VERSION ""

NS_ :

BS_:

BU_: Display VN1640A IMU_R LOGGER EPOS RES FSG_LOGGER IO_TEST JETSON ASB AMI ECU RTK IMU_F I2C_RW I2C_SB_L I2C_SB_R I2C_FW HSS_FAN_L HSS_FAN_R HSS_PUMP_L HSS_PUMP_R HSS_RTDS HSS_REAR DIO_AS DIO_DASH AIN_R1 AIN_SB_L AIN_SB_R AIN_F2 AIN_F1
VAL_TABLE_ VT_Car_Status 6 "SCS ERROR" 5 "LC ON" 4 "DRIVE" 3 "Wait for RTD" 2 "RTD OFF" 1 "Wait for TSA" 0 "Undefined | Startup" ;
VAL_TABLE_ VT_CANopen_Request_State 130 "Reset Communication" 129 "Reset Application" 2 "Stopped Mode" 128 "Pre-Operational Mode" 1 "Operational Mode" ;
VAL_TABLE_ VT_CANopen_Node_Status 255 "PRE-OPERATIONAL" 245 "OPERATIONAL" 244 "STOPPED" 240 "BOOTUP" 127 "PRE-OPERATIONAL" 5 "OPERATIONAL" 4 "STOPPED" 0 "BOOTUP" ;
VAL_TABLE_ VT_CANopen_Addressed_Node_ID 17 "RES" 12 "EPOS" 0 "all" ;
VAL_TABLE_ VT_CANopen_Nodes 17 "RES" 12 "EPOS" 0 "all" ;
VAL_TABLE_ VT_LED_States 3 "Error" 2 "Start-up Test" 1 "ON" 0 "OFF" ;
VAL_TABLE_ VT_Corners 3 "Front Left" 2 "Rear Left" 1 "Rear Right" 0 "Front Right" ;
VAL_TABLE_ VT_Sides 1 "Left" 0 "Right" ;

BO_ 3221225472 VECTOR__INDEPENDENT_SIG_MSG: 0 Vector__XXX
 SG_ sig_imu_power_ok : 0|1@1+ (1,0) [0|1] "" Vector__XXX
 SG_ diff_correction_age : 0|8@1+ (1,0) [0|255] "s" Vector__XXX
 SG_ num_space_vehicles : 0|8@1+ (1,0) [0|255] "" Vector__XXX

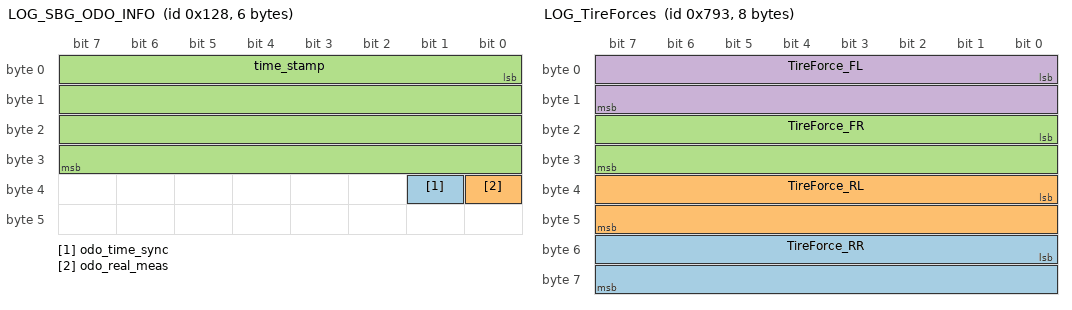
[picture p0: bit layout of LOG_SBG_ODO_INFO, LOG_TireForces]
BO_ 296 LOG_SBG_ODO_INFO: 6 Vector__XXX
 SG_ odo_time_sync : 33|1@1+ (1,0) [0|1] "" Vector__XXX
 SG_ odo_real_meas : 32|1@1+ (1,0) [0|1] "" Vector__XXX
 SG_ time_stamp : 0|32@1+ (1,0) [0|4294967295] "us" Vector__XXX

BO_ 288 HSC_SBG_POSITION_ACC: 6 RTK
 SG_ altitude_acc : 32|16@1+ (0.01,0) [0|655.35] "m" Vector__XXX
 SG_ latitude_acc : 0|16@1+ (0.01,0) [0|655.35] "m" Vector__XXX
 SG_ longitude_acc : 16|16@1+ (0.01,0) [0|655.35] "m" Vector__XXX

BO_ 285 HSC_SBG_EULER_ACC: 6 RTK
 SG_ yaw_acc : 32|16@1+ (0.0001,0) [0|6.5535] "rad" Vector__XXX
 SG_ pitch_acc : 16|16@1+ (0.01,0) [0|655.35] "°" Vector__XXX
 SG_ roll_acc : 0|16@1+ (0.0001,0) [0|6.5535] "rad" Vector__XXX

BO_ 284 HSC_SBG_EULER: 6 RTK
 SG_ yaw : 32|16@1- (0.0001,0) [-3.2768|3.2767] "rad" Vector__XXX
 SG_ pitch : 16|16@1- (0.0001,0) [-3.2768|3.2767] "rad" Vector__XXX
 SG_ roll : 0|16@1- (0.0001,0) [-3.2768|3.2767] "rad" Vector__XXX

BO_ 282 LOG_SBG_EKF_INFO: 4 RTK
 SG_ time_stamp : 0|32@1+ (1,0) [0|4294967295] "us" Vector__XXX

BO_ 277 LOG_SBG_IMU_INFO: 8 RTK
 SG_ temperature : 48|16@1- (0.01,0) [-327.68|327.67] "" Vector__XXX
 SG_ time_stamp : 0|32@1+ (1,0) [0|4294967295] "us" Vector__XXX

BO_ 1939 LOG_TireForces: 8 ECU
 SG_ TireForce_RR : 48|16@1+ (0.02,0) [0|1310.7] "N" Vector__XXX
 SG_ TireForce_RL : 32|16@1+ (0.02,0) [0|1310.7] "N" Vector__XXX
 SG_ TireForce_FR : 16|16@1+ (0.02,0) [0|1310.7] "N" Vector__XXX
 SG_ TireForce_FL : 0|16@1+ (0.02,0) [0|1310.7] "N" Vector__XXX

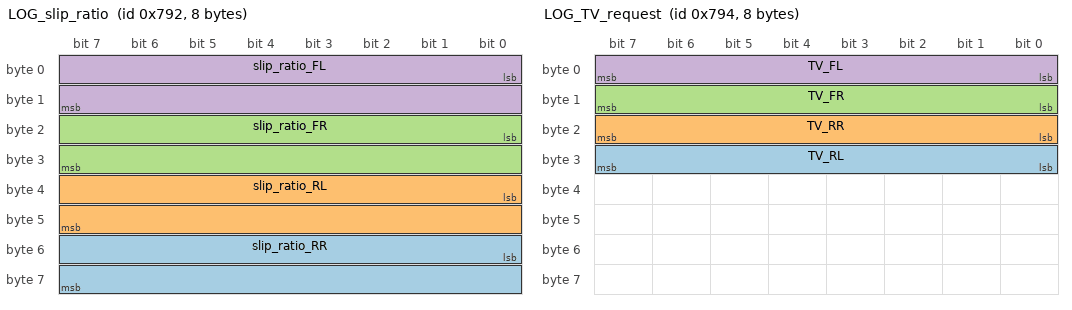
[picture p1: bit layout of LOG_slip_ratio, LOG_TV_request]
BO_ 1938 LOG_slip_ratio: 8 ECU
 SG_ slip_ratio_RR : 48|16@1- (0.01,0) [-327.68|327.67] "rad" Vector__XXX
 SG_ slip_ratio_RL : 32|16@1- (0.01,0) [-327.68|327.67] "rad" Vector__XXX
 SG_ slip_ratio_FR : 16|16@1- (0.01,0) [-327.68|327.67] "rad" Vector__XXX
 SG_ slip_ratio_FL : 0|16@1- (0.01,0) [-327.68|327.67] "rad" Vector__XXX

BO_ 1940 LOG_TV_request: 8 ECU
 SG_ TV_RL : 24|8@1- (0.2,0) [-25.6|25.4] "Nm" Vector__XXX
 SG_ TV_RR : 16|8@1- (0.2,0) [-25.6|25.4] "Nm" Vector__XXX
 SG_ TV_FR : 8|8@1- (0.2,0) [-25.6|25.4] "Nm" Vector__XXX
 SG_ TV_FL : 0|8@1- (0.2,0) [-25.6|25.4] "Nm" Vector__XXX

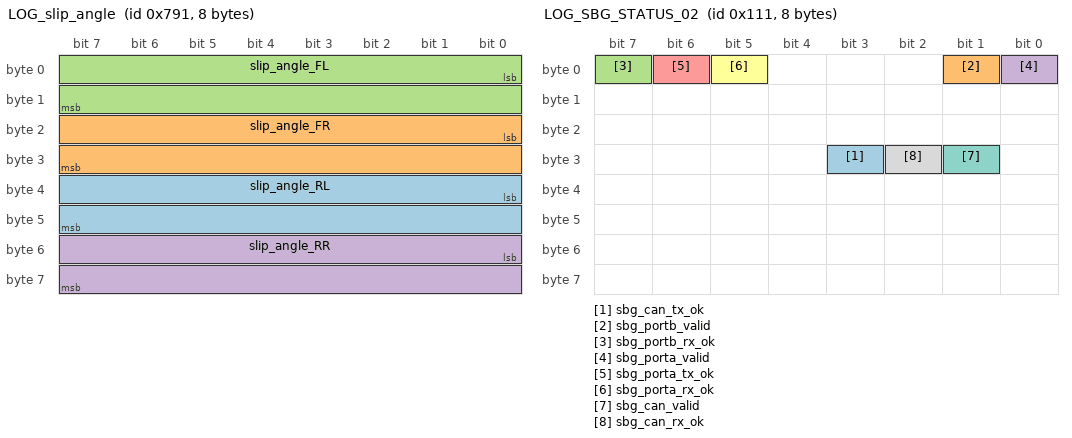
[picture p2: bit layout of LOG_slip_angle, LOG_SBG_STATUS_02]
BO_ 1937 LOG_slip_angle: 8 ECU
 SG_ slip_angle_RL : 32|16@1- (0.01,0) [-327.68|327.67] "rad" Vector__XXX
 SG_ slip_angle_FR : 16|16@1- (0.01,0) [-327.68|327.67] "rad" Vector__XXX
 SG_ slip_angle_FL : 0|16@1- (0.01,0) [-327.68|327.67] "rad" Vector__XXX
 SG_ slip_angle_RR : 48|16@1- (0.01,0) [-327.68|327.67] "rad" Vector__XXX

BO_ 310 HSC_SBG_TRUE_HEADING: 8 RTK
 SG_ pitch : 32|16@1- (0.01,0) [-327.68|327.67] "°" Vector__XXX
 SG_ true_heading_acc : 16|16@1+ (0.01,0) [0|655.35] "°" Vector__XXX
 SG_ true_heading : 0|16@1+ (0.01,0) [0|655.35] "°" Vector__XXX

BO_ 287 HSC_SBG_ALTITUDE: 6 RTK
 SG_ undulation : 32|16@1- (0.005,0) [-163.84|163.835] "m" Vector__XXX
 SG_ altitude : 0|32@1- (0.001,0) [-2147483.648|2147483.647] "m" Vector__XXX

BO_ 286 HSC_SBG_POSITION: 8 RTK
 SG_ longitude : 32|32@1- (1E-007,0) [-214.7483648|214.7483647] "°" Vector__XXX
 SG_ latitude : 0|32@1- (1E-007,0) [-214.7483648|214.7483647] "°" Vector__XXX

BO_ 309 LOG_SBG_HEADING_INFO: 6 RTK
 SG_ time_stamp : 0|32@1+ (1,0) [0|4294967295] "us" Vector__XXX

BO_ 305 LOG_SBG_POS_INFO: 8 RTK
 SG_ time_stamp : 0|32@1+ (1,0) [0|4294967295] "us" Vector__XXX

BO_ 301 LOG_SBG_GPS1_VEL_INFO: 8 RTK
 SG_ time_stamp : 0|32@1+ (1,0) [0|4294967295] "us" Vector__XXX

BO_ 274 LOG_SBG_STATUS_03: 6 RTK

BO_ 273 LOG_SBG_STATUS_02: 8 RTK
 SG_ sbg_can_tx_ok : 27|1@1+ (1,0) [0|1] "" Vector__XXX
 SG_ sbg_portb_valid : 1|1@1+ (1,0) [0|1] "" Vector__XXX
 SG_ sbg_portb_rx_ok : 7|1@1+ (1,0) [0|1] "" Vector__XXX
 SG_ sbg_porta_valid : 0|1@1+ (1,0) [0|1] "" Vector__XXX
 SG_ sbg_porta_tx_ok : 6|1@1+ (1,0) [0|1] "" Vector__XXX
 SG_ sbg_porta_rx_ok : 5|1@1+ (1,0) [0|1] "" Vector__XXX
 SG_ sbg_can_valid : 25|1@1+ (1,0) [0|1] "" Vector__XXX
 SG_ sbg_can_rx_ok : 26|1@1+ (1,0) [0|1] "" Vector__XXX

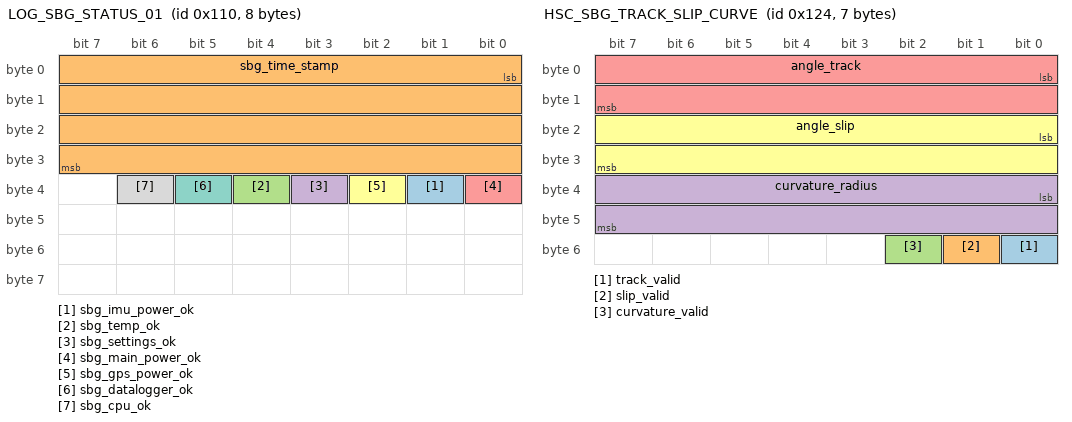
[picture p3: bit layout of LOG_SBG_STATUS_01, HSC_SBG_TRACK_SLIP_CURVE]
BO_ 272 LOG_SBG_STATUS_01: 8 RTK
 SG_ sbg_imu_power_ok : 33|1@1+ (1,0) [0|1] "" Vector__XXX
 SG_ sbg_time_stamp : 0|32@1+ (1,0) [0|4294967295] "us" Vector__XXX
 SG_ sbg_temp_ok : 36|1@1+ (1,0) [0|1] "" Vector__XXX
 SG_ sbg_settings_ok : 35|1@1+ (1,0) [0|1] "" Vector__XXX
 SG_ sbg_main_power_ok : 32|1@1+ (1,0) [0|1] "" Vector__XXX
 SG_ sbg_gps_power_ok : 34|1@1+ (1,0) [0|1] "" Vector__XXX
 SG_ sbg_datalogger_ok : 37|1@1+ (1,0) [0|1] "" Vector__XXX
 SG_ sbg_cpu_ok : 38|1@1+ (1,0) [0|1] "" Vector__XXX

BO_ 292 HSC_SBG_TRACK_SLIP_CURVE: 7 RTK
 SG_ track_valid : 48|1@1+ (1,0) [0|1] "" Vector__XXX
 SG_ slip_valid : 49|1@1+ (1,0) [0|1] "" Vector__XXX
 SG_ curvature_valid : 50|1@1+ (1,0) [0|1] "" Vector__XXX
 SG_ curvature_radius : 32|16@1+ (0.01,0) [0|655.35] "m" Vector__XXX
 SG_ angle_track : 0|16@1- (0.0001,0) [-3.2768|3.2767] "rad" Vector__XXX
 SG_ angle_slip : 16|16@1- (0.0001,0) [-3.2768|3.2767] "rad" Vector__XXX

BO_ 291 HSC_SBG_EKF_VEL_BODY: 6 RTK
 SG_ velocity_z : 32|16@1- (0.01,0) [-327.68|327.67] "m/s" Vector__XXX
 SG_ velocity_y : 16|16@1- (0.01,0) [0|0] "m/s" Vector__XXX
 SG_ velocity_x : 0|16@1- (0.01,0) [-327.68|327.67] "m/s" Vector__XXX

BO_ 279 HSC_SBG_GYRO: 6 RTK
 SG_ gyro_z : 32|16@1- (0.001,0) [-32.768|32.767] "rad/s" Vector__XXX
 SG_ gyro_y : 16|16@1- (0.001,0) [-32.768|32.767] "rad/s" Vector__XXX
 SG_ gyro_x : 0|16@1- (0.001,0) [-32.768|32.767] "rad/s" Vector__XXX

BO_ 278 HSC_SBG_ACCEL: 6 RTK
 SG_ accel_z : 32|16@1- (0.01,0) [-327.68|327.67] "m/s^2" Vector__XXX
 SG_ accel_y : 16|16@1- (0.01,0) [-327.68|327.67] "m/s^2" Vector__XXX
 SG_ accel_x : 0|16@1- (0.01,0) [-327.68|327.67] "m/s^2" Vector__XXX

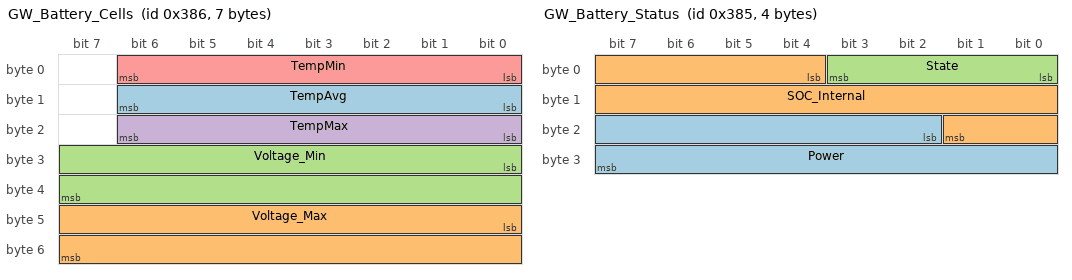
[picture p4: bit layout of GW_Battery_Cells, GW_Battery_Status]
BO_ 902 GW_Battery_Cells: 7 ECU
 SG_ TempAvg : 8|7@1+ (1,0) [0|127] "°C"  VN1640A,LOGGER,Display
 SG_ Voltage_Max : 40|16@1+ (0.001,0) [0|65.535] "V"  Display,LOGGER,VN1640A
 SG_ Voltage_Min : 24|16@1+ (0.001,0) [0|65.535] "V"  Display,LOGGER,VN1640A
 SG_ TempMax : 16|7@1+ (1,0) [0|127] "°C"  Display,LOGGER,VN1640A
 SG_ TempMin : 0|7@1+ (1,0) [0|127] "°C"  Display,LOGGER,VN1640A

BO_ 901 GW_Battery_Status: 4 ECU
 SG_ Power : 18|14@1+ (0.01,0) [0|163.83] "kW"  Display
 SG_ SOC_Internal : 4|14@1+ (0.01,0) [0|163.83] "%"  Display
 SG_ State : 0|4@1+ (1,0) [0|15] ""  Display

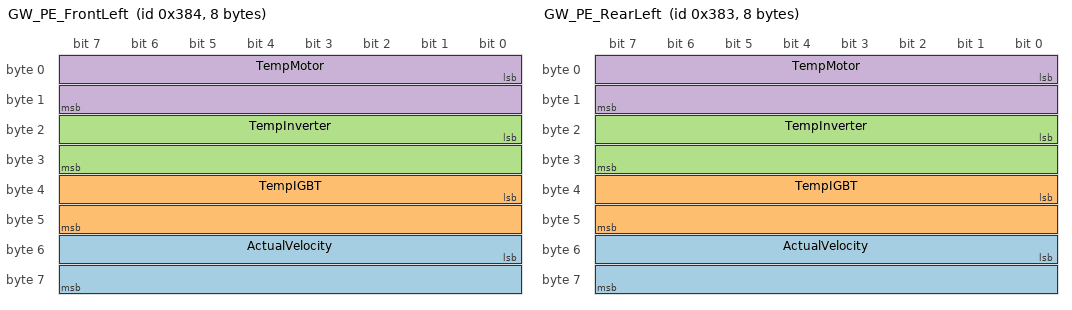
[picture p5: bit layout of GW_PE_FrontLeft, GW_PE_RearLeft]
BO_ 900 GW_PE_FrontLeft: 8 ECU
 SG_ ActualVelocity : 48|16@1- (1,0) [-32768|32767] "U/min"  VN1640A,LOGGER
 SG_ TempIGBT : 32|16@1- (0.1,0) [-3276.8|3276.7] "°C"  VN1640A,LOGGER,Display
 SG_ TempInverter : 16|16@1- (0.1,0) [-3276.8|3276.7] "°C"  VN1640A,LOGGER,Display
 SG_ TempMotor : 0|16@1- (0.1,0) [-3276.8|3276.7] "°C"  VN1640A,LOGGER,Display

BO_ 899 GW_PE_RearLeft: 8 ECU
 SG_ ActualVelocity : 48|16@1- (1,0) [-32768|32767] "U/min"  VN1640A,LOGGER
 SG_ TempIGBT : 32|16@1- (0.1,0) [-3276.8|3276.7] "°C"  VN1640A,LOGGER,Display
 SG_ TempInverter : 16|16@1- (0.1,0) [-3276.8|3276.7] "°C"  VN1640A,LOGGER,Display
 SG_ TempMotor : 0|16@1- (0.1,0) [-3276.8|3276.7] "°C"  VN1640A,LOGGER,Display

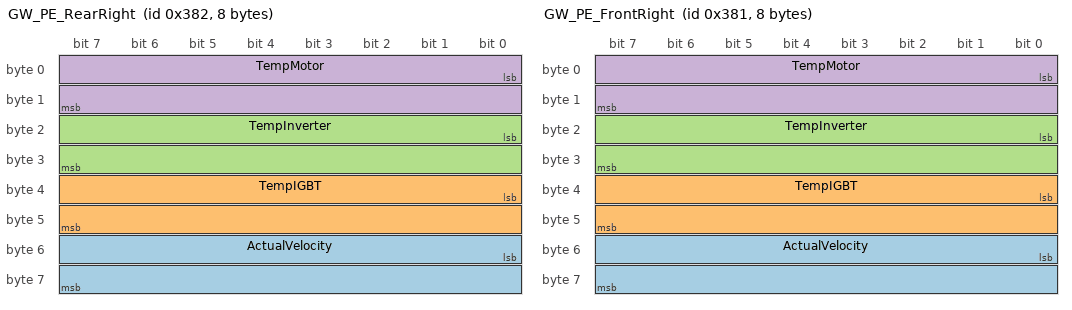
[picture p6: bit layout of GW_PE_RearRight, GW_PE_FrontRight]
BO_ 898 GW_PE_RearRight: 8 ECU
 SG_ ActualVelocity : 48|16@1- (1,0) [-32768|32767] "U/min"  VN1640A,LOGGER
 SG_ TempIGBT : 32|16@1- (0.1,0) [-3276.8|3276.7] "°C"  VN1640A,LOGGER,Display
 SG_ TempInverter : 16|16@1- (0.1,0) [-3276.8|3276.7] "°C"  VN1640A,LOGGER,Display
 SG_ TempMotor : 0|16@1- (0.1,0) [-3276.8|3276.7] "°C"  VN1640A,LOGGER,Display

BO_ 897 GW_PE_FrontRight: 8 ECU
 SG_ ActualVelocity : 48|16@1- (1,0) [-32768|32767] "U/min"  LOGGER,VN1640A
 SG_ TempIGBT : 32|16@1- (0.1,0) [-3276.8|3276.7] "°C"  LOGGER,VN1640A,Display
 SG_ TempInverter : 16|16@1- (0.1,0) [-3276.8|3276.7] "°C"  LOGGER,VN1640A,Display
 SG_ TempMotor : 0|16@1- (0.1,0) [-3276.8|3276.7] "°C"  LOGGER,VN1640A,Display

BO_ 1042 EXC_BATFAN_Control: 1 ECU
 SG_ Fan_request : 0|7@1+ (1,0) [0|127] ""  LOGGER,VN1640A,HSS_REAR
 SG_ Fan_On : 7|1@1+ (1,0) [0|1] ""  LOGGER,VN1640A,HSS_REAR

BO_ 1936 LOG_ASSILEDs: 1 DIO_AS
 SG_ Blue : 2|1@1+ (1,0) [0|1] ""  VN1640A,LOGGER
 SG_ Yellow : 0|1@1+ (1,0) [0|1] ""  VN1640A,LOGGER

BO_ 263 HSC_IMU_Rear: 8 IMU_R

BO_ 262 HSC_IMU_Front: 8 IMU_F

BO_ 1039 EXC_FAN_Control: 1 ECU
 SG_ Fan_On : 7|1@1+ (1,0) [0|1] ""  HSS_FAN_L,HSS_FAN_R,VN1640A,LOGGER
 SG_ Fan_request : 0|7@1+ (1,0) [0|127] ""  HSS_FAN_L,HSS_FAN_R,VN1640A,LOGGER

BO_ 1040 EXC_PUMP_Control: 1 ECU
 SG_ Pump_On : 7|1@1+ (1,0) [0|1] ""  HSS_PUMP_R,HSS_PUMP_L,VN1640A,LOGGER
 SG_ Pump_request : 0|7@1+ (1,0) [0|127] ""  HSS_PUMP_R,HSS_PUMP_L,VN1640A,LOGGER

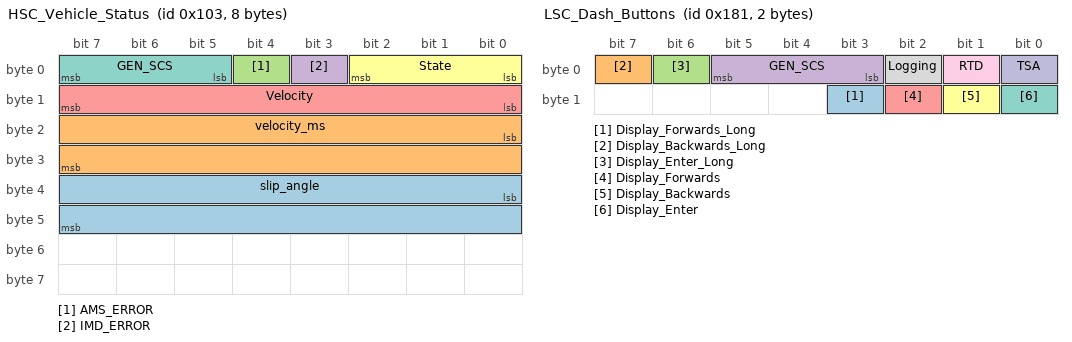
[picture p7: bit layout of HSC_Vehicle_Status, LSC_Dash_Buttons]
BO_ 259 HSC_Vehicle_Status: 8 ECU
 SG_ slip_angle : 32|16@1- (0.01,0) [-327.68|327.67] "rad" Vector__XXX
 SG_ velocity_ms : 16|16@1- (0.001,0) [-32.768|32.767] "m/s" Vector__XXX
 SG_ AMS_ERROR : 4|1@1+ (1,0) [0|1] ""  Display,VN1640A,LOGGER,DIO_DASH
 SG_ IMD_ERROR : 3|1@1+ (1,0) [0|1] ""  Display,VN1640A,LOGGER,DIO_DASH
 SG_ Velocity : 8|8@1+ (0.5,0) [0|127.5] "km/h"  Display,VN1640A,LOGGER
 SG_ State : 0|3@1+ (1,0) [0|7] ""  Display,VN1640A,LOGGER,HSS_RTDS
 SG_ GEN_SCS : 5|3@1+ (1,0) [0|7] ""  Display,DIO_DASH,VN1640A,LOGGER,HSS_RTDS

BO_ 386 LSC_Extern_Buttons: 1 DIO_AS
 SG_ TSA : 0|1@1+ (1,0) [0|1] ""  ECU,VN1640A,LOGGER
 SG_ GEN_SCS : 1|3@1+ (1,0) [0|7] ""  ECU,VN1640A,LOGGER

BO_ 385 LSC_Dash_Buttons: 2 DIO_DASH
 SG_ Display_Forwards_Long : 11|1@1+ (1,0) [0|1] ""  Display,LOGGER,VN1640A
 SG_ Display_Backwards_Long : 7|1@1+ (1,0) [0|1] ""  Display,LOGGER,VN1640A
 SG_ Display_Enter_Long : 6|1@1+ (1,0) [0|1] ""  VN1640A,Display,LOGGER
 SG_ GEN_SCS : 3|3@1+ (1,0) [0|7] ""  Display,VN1640A,LOGGER,ECU
 SG_ Display_Forwards : 10|1@1+ (1,0) [0|1] ""  VN1640A,Display,LOGGER
 SG_ Display_Backwards : 9|1@1+ (1,0) [0|1] ""  VN1640A,Display,LOGGER
 SG_ Display_Enter : 8|1@1+ (1,0) [0|1] ""  VN1640A,Display,LOGGER
 SG_ Logging : 2|1@1+ (1,0) [0|1] ""  VN1640A,Display,LOGGER,ECU
 SG_ RTD : 1|1@1+ (1,0) [0|1] ""  VN1640A,LOGGER,ECU
 SG_ TSA : 0|1@1+ (1,0) [0|1] ""  VN1640A,LOGGER,ECU

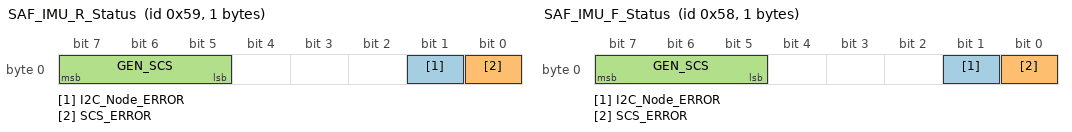
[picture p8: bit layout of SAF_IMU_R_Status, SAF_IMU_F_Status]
BO_ 89 SAF_IMU_R_Status: 1 IMU_R
 SG_ I2C_Node_ERROR : 1|1@1+ (1,0) [0|1] ""  VN1640A,LOGGER
 SG_ SCS_ERROR : 0|1@1+ (1,0) [0|1] ""  ECU,VN1640A,LOGGER
 SG_ GEN_SCS : 5|3@1+ (1,0) [0|7] ""  ECU,VN1640A,LOGGER

BO_ 88 SAF_IMU_F_Status: 1 IMU_F
 SG_ I2C_Node_ERROR : 1|1@1+ (1,0) [0|1] ""  VN1640A,LOGGER
 SG_ SCS_ERROR : 0|1@1+ (1,0) [0|1] ""  ECU,VN1640A,LOGGER
 SG_ GEN_SCS : 5|3@1+ (1,0) [0|7] ""  ECU,VN1640A,LOGGER

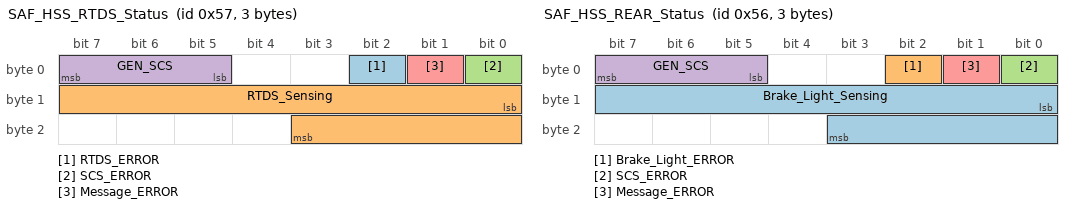
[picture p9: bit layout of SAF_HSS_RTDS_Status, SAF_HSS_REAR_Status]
BO_ 87 SAF_HSS_RTDS_Status: 3 HSS_RTDS
 SG_ RTDS_ERROR : 2|1@1+ (1,0) [0|1] ""  VN1640A,LOGGER
 SG_ RTDS_Sensing : 8|12@1+ (1,0) [0|4095] "mA"  VN1640A,LOGGER
 SG_ SCS_ERROR : 0|1@1+ (1,0) [0|1] ""  ECU,VN1640A,LOGGER
 SG_ GEN_SCS : 5|3@1+ (1,0) [0|7] ""  ECU,VN1640A,LOGGER
 SG_ Message_ERROR : 1|1@1+ (1,0) [0|1] ""  VN1640A,LOGGER

BO_ 86 SAF_HSS_REAR_Status: 3 HSS_REAR
 SG_ Brake_Light_Sensing : 8|12@1+ (1,0) [0|4095] "mA"  LOGGER,VN1640A
 SG_ Brake_Light_ERROR : 2|1@1+ (1,0) [0|1] ""  LOGGER,VN1640A
 SG_ SCS_ERROR : 0|1@1+ (1,0) [0|1] ""  LOGGER,VN1640A,ECU
 SG_ GEN_SCS : 5|3@1+ (1,0) [0|7] ""  LOGGER,VN1640A,ECU
 SG_ Message_ERROR : 1|1@1+ (1,0) [0|1] ""  LOGGER,VN1640A

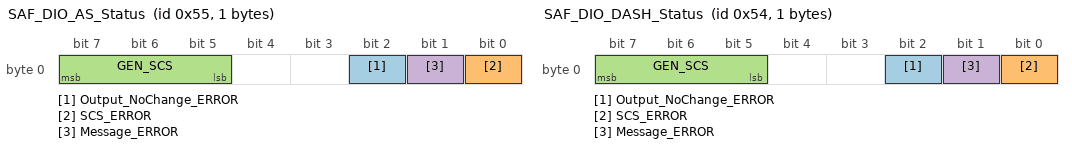
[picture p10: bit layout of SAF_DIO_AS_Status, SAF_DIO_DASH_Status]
BO_ 85 SAF_DIO_AS_Status: 1 DIO_AS
 SG_ Output_NoChange_ERROR : 2|1@1+ (1,0) [0|1] ""  LOGGER,VN1640A
 SG_ SCS_ERROR : 0|1@1+ (1,0) [0|1] ""  VN1640A,LOGGER,ECU
 SG_ GEN_SCS : 5|3@1+ (1,0) [0|7] ""  VN1640A,LOGGER,ECU
 SG_ Message_ERROR : 1|1@1+ (1,0) [0|1] ""  LOGGER,VN1640A

BO_ 84 SAF_DIO_DASH_Status: 1 DIO_DASH
 SG_ Output_NoChange_ERROR : 2|1@1+ (1,0) [0|1] ""  LOGGER,VN1640A
 SG_ SCS_ERROR : 0|1@1+ (1,0) [0|1] ""  VN1640A,LOGGER,ECU
 SG_ GEN_SCS : 5|3@1+ (1,0) [0|7] ""  VN1640A,LOGGER,ECU
 SG_ Message_ERROR : 1|1@1+ (1,0) [0|1] ""  LOGGER,VN1640A

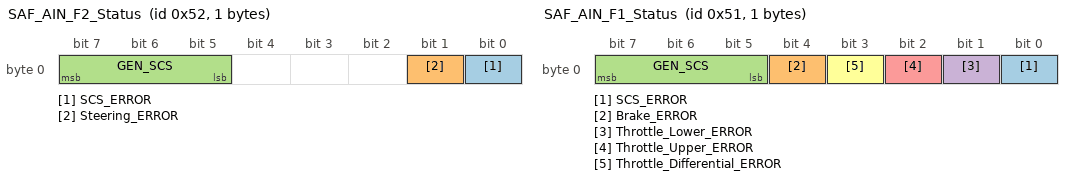
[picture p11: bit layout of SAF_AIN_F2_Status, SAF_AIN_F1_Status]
BO_ 82 SAF_AIN_F2_Status: 1 AIN_F2
 SG_ SCS_ERROR : 0|1@1+ (1,0) [0|1] ""  JETSON,ECU,VN1640A,LOGGER
 SG_ Steering_ERROR : 1|1@1+ (1,0) [0|1] ""  VN1640A,LOGGER
 SG_ GEN_SCS : 5|3@1+ (1,0) [0|7] ""  JETSON,ECU,VN1640A,LOGGER

BO_ 81 SAF_AIN_F1_Status: 1 AIN_F1
 SG_ SCS_ERROR : 0|1@1+ (1,0) [0|1] ""  ECU,VN1640A,LOGGER
 SG_ Brake_ERROR : 4|1@1+ (1,0) [0|1] ""  VN1640A,LOGGER
 SG_ GEN_SCS : 5|3@1+ (1,0) [0|7] ""  ECU,VN1640A,LOGGER
 SG_ Throttle_Lower_ERROR : 1|1@1+ (1,0) [0|1] ""  VN1640A,LOGGER
 SG_ Throttle_Upper_ERROR : 2|1@1+ (1,0) [0|1] ""  VN1640A,LOGGER
 SG_ Throttle_Differential_ERROR : 3|1@1+ (1,0) [0|1] ""  VN1640A,LOGGER

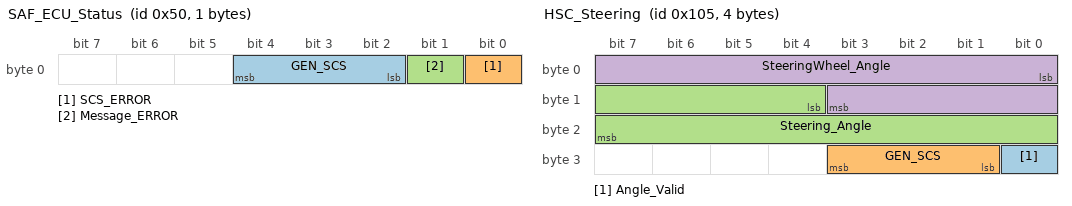
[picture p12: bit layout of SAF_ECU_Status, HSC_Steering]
BO_ 80 SAF_ECU_Status: 1 ECU
 SG_ GEN_SCS : 2|3@1+ (1,0) [0|7] ""  JETSON,VN1640A,LOGGER
 SG_ SCS_ERROR : 0|1@1+ (1,0) [0|1] ""  JETSON,VN1640A,LOGGER
 SG_ Message_ERROR : 1|1@1+ (1,0) [0|1] ""  VN1640A,LOGGER

BO_ 261 HSC_Steering: 4 AIN_F2
 SG_ Angle_Valid : 24|1@1+ (1,0) [0|1] ""  JETSON,ECU,VN1640A,LOGGER
 SG_ GEN_SCS : 25|3@1+ (1,0) [0|7] ""  JETSON,VN1640A,LOGGER,ECU
 SG_ Steering_Angle : 12|12@1- (0.075,0) [-153.6|153.525] "°"  JETSON,VN1640A,LOGGER,ECU
 SG_ SteeringWheel_Angle : 0|12@1- (0.075,0) [-153.6|153.525] "°"  JETSON,VN1640A,LOGGER,ECU

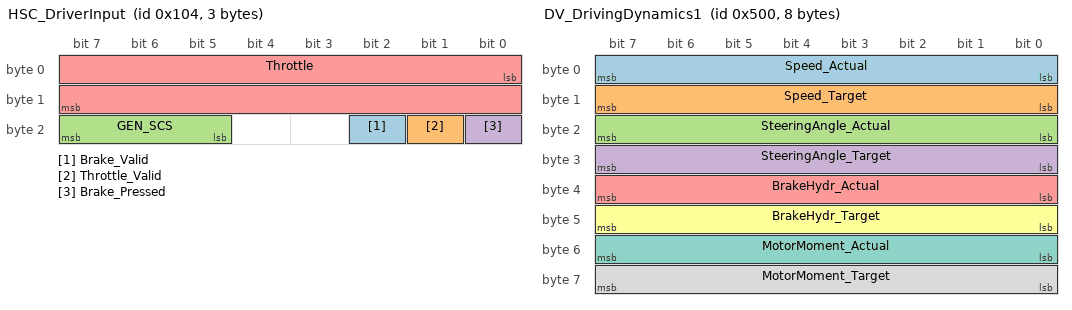
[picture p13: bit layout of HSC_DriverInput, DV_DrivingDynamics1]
BO_ 260 HSC_DriverInput: 3 AIN_F1
 SG_ Brake_Valid : 18|1@1+ (1,0) [0|1] ""  ECU,VN1640A,LOGGER,HSS_REAR
 SG_ Throttle_Valid : 17|1@1+ (1,0) [0|1] ""  ECU,VN1640A,LOGGER
 SG_ GEN_SCS : 21|3@1+ (1,0) [0|7] ""  VN1640A,LOGGER,HSS_REAR,ECU
 SG_ Brake_Pressed : 16|1@1+ (1,0) [0|1] ""  VN1640A,LOGGER,HSS_REAR,ECU
 SG_ Throttle : 0|16@1+ (0.002,0) [0|100] "%"  VN1640A,LOGGER,ECU

BO_ 1809 CANO_RES_NMT_EC: 1 RES

BO_ 1804 CANO_EPOS_NMT_EC: 1 EPOS

BO_ 1553 CANO_RES_RSDO: 8 RES

BO_ 1548 CANO_EPOS_RSDO: 8 EPOS

BO_ 1425 CANO_RES_TSDO: 8 RES

BO_ 1420 CANO_EPOS_TSDO: 8 EPOS

BO_ 1300 DV_FREE_TO_USE_2: 0 JETSON

BO_ 145 CANO_RES_EMCY: 8 RES

BO_ 1297 DV_SCS_Errors: 8 JETSON

BO_ 1285 DV_AMI_Status: 1 AMI
 SG_ State : 0|3@1+ (1,0) [0|6] ""  VN1640A,LOGGER,JETSON
 SG_ GEN_SCS : 3|3@1+ (1,0) [0|7] ""  VN1640A,LOGGER,JETSON

BO_ 1299 DV_ASB_Pressure: 3 ASB
 SG_ Pressure2 : 12|12@1+ (4,0) [0|16380] "mbar"  VN1640A,LOGGER,JETSON
 SG_ Pressure1 : 0|12@1+ (4,0) [0|16380] "mbar"  VN1640A,LOGGER,JETSON

BO_ 1280 DV_DrivingDynamics1: 8 JETSON
 SG_ Speed_Actual : 0|8@1+ (1,0) [0|255] "km/h"  VN1640A,LOGGER,FSG_LOGGER
 SG_ Speed_Target : 8|8@1+ (1,0) [0|255] "km/h"  VN1640A,LOGGER,FSG_LOGGER
 SG_ SteeringAngle_Actual : 16|8@1- (0.5,0) [-64|63.5] "deg"  VN1640A,LOGGER,FSG_LOGGER
 SG_ SteeringAngle_Target : 24|8@1- (0.5,0) [-64|63.5] "deg"  VN1640A,LOGGER,FSG_LOGGER
 SG_ BrakeHydr_Actual : 32|8@1+ (1,0) [0|100] "%"  VN1640A,LOGGER,FSG_LOGGER
 SG_ BrakeHydr_Target : 40|8@1+ (1,0) [0|100] "%"  VN1640A,LOGGER,FSG_LOGGER
 SG_ MotorMoment_Actual : 48|8@1- (1,0) [-100|100] "%"  VN1640A,LOGGER,FSG_LOGGER
 SG_ MotorMoment_Target : 56|8@1- (1,0) [-100|100] "%"  VN1640A,LOGGER,FSG_LOGGER

BO_ 1281 DV_DrivingDynamics2: 6 JETSON
 SG_ Acceleration_Longitudinal : 0|16@1- (0.001953125,0) [-64|63.998046875] "m/s2"  VN1640A,LOGGER,FSG_LOGGER
 SG_ Acceleration_Lateral : 16|16@1- (0.001953125,0) [-64|63.998046875] "m/s2"  VN1640A,LOGGER,FSG_LOGGER
 SG_ YawRate : 32|16@1- (0.0078125,0) [-256|255.9921875] "deg/s"  VN1640A,LOGGER,FSG_LOGGER

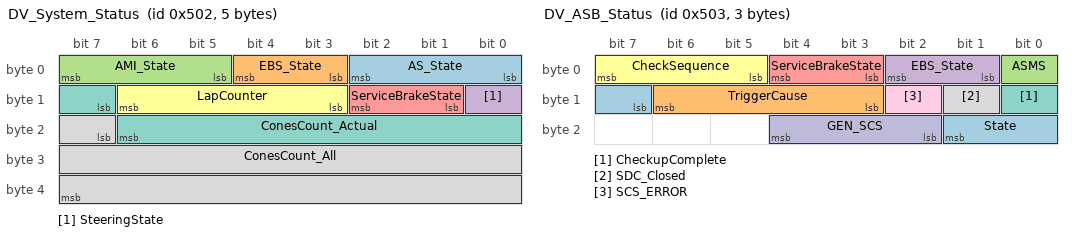
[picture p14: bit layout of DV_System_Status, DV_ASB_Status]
BO_ 1282 DV_System_Status: 5 JETSON
 SG_ AS_State : 0|3@1+ (1,0) [0|5] ""  VN1640A,LOGGER,HSS_RTDS,DIO_AS,FSG_LOGGER
 SG_ EBS_State : 3|2@1+ (1,0) [0|3] ""  VN1640A,LOGGER,FSG_LOGGER
 SG_ AMI_State : 5|3@1+ (1,0) [0|6] ""  VN1640A,LOGGER,FSG_LOGGER
 SG_ SteeringState : 8|1@1+ (1,0) [0|1] ""  VN1640A,LOGGER,FSG_LOGGER
 SG_ ServiceBrakeState : 9|2@1+ (1,0) [0|3] ""  VN1640A,LOGGER,FSG_LOGGER
 SG_ LapCounter : 11|4@1+ (1,0) [0|15] ""  VN1640A,LOGGER,FSG_LOGGER
 SG_ ConesCount_Actual : 15|8@1+ (1,0) [0|255] ""  VN1640A,LOGGER,FSG_LOGGER
 SG_ ConesCount_All : 23|17@1+ (1,0) [0|131071] ""  VN1640A,LOGGER,FSG_LOGGER

BO_ 1283 DV_ASB_Status: 3 ASB
 SG_ State : 15|3@1+ (1,0) [0|7] "" Vector__XXX
 SG_ TriggerCause : 11|4@1+ (1,0) [0|15] "" Vector__XXX
 SG_ ASMS : 0|1@1+ (1,0) [0|1] ""  VN1640A,LOGGER,JETSON
 SG_ EBS_State : 1|2@1+ (1,0) [0|3] ""  VN1640A,LOGGER,JETSON
 SG_ ServiceBrakeState : 3|2@1+ (1,0) [0|3] ""  VN1640A,LOGGER,JETSON
 SG_ CheckSequence : 5|3@1+ (1,0) [0|7] ""  VN1640A,LOGGER,JETSON
 SG_ CheckupComplete : 8|1@1+ (1,0) [0|1] ""  VN1640A,LOGGER,JETSON
 SG_ SDC_Closed : 9|1@1+ (1,0) [0|1] ""  VN1640A,LOGGER,JETSON
 SG_ SCS_ERROR : 10|1@1+ (1,0) [0|1] ""  VN1640A,LOGGER,JETSON
 SG_ GEN_SCS : 18|3@1+ (1,0) [0|7] ""  VN1640A,LOGGER,JETSON

BO_ 1169 CANO_RES_TPDO4: 0 RES

BO_ 913 CANO_RES_TPDO3: 0 RES

BO_ 657 CANO_RES_TPDO2: 0 RES

BO_ 1041 CANO_RES_RPDO3: 0 JETSON

BO_ 785 CANO_RES_RPDO2: 0 JETSON

BO_ 529 CANO_RES_RPDO1: 0 JETSON

BO_ 1292 CANO_EPOS_RPDO4: 6 JETSON
 SG_ controlword : 0|16@1+ (1,0) [0|255] ""  VN1640A,LOGGER,EPOS
 SG_ target_velocity : 16|32@1- (1,0) [-2147483648|2147483647] ""  VN1640A,LOGGER,EPOS

BO_ 1036 CANO_EPOS_RPDO3: 6 JETSON
 SG_ controlword : 0|16@1+ (1,0) [0|255] ""  LOGGER,VN1640A,EPOS
 SG_ target_position : 16|32@1- (1,0) [-2147483648|2147483647] ""  LOGGER,VN1640A,EPOS

BO_ 780 CANO_EPOS_RPDO2: 3 JETSON
 SG_ controlword : 0|16@1+ (1,0) [0|255] ""  VN1640A,LOGGER,EPOS
 SG_ modes_of_operation : 16|8@1+ (1,0) [0|255] ""  VN1640A,LOGGER,EPOS

BO_ 524 CANO_EPOS_RPDO1: 2 JETSON
 SG_ controlword : 0|16@1+ (1,0) [0|255] ""  LOGGER,VN1640A,EPOS

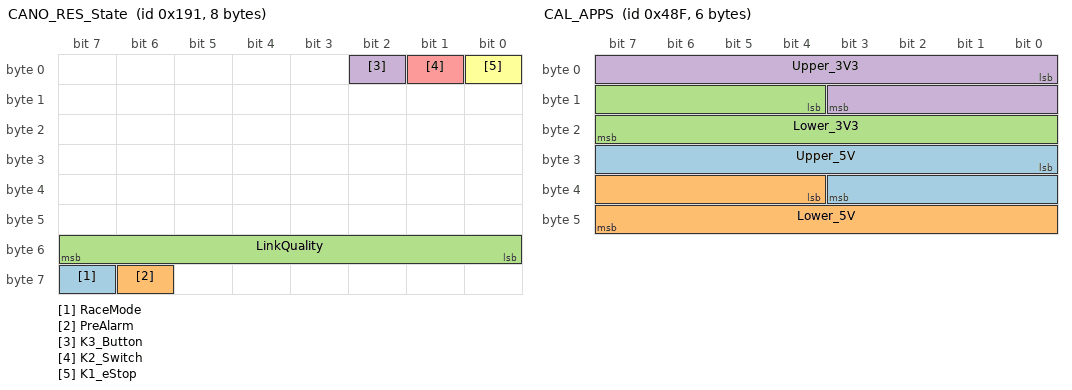
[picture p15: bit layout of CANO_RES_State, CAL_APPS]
BO_ 401 CANO_RES_State: 8 RES
 SG_ RaceMode : 63|1@1+ (1,0) [0|1] ""  VN1640A,LOGGER,JETSON
 SG_ PreAlarm : 62|1@1+ (1,0) [0|0] ""  VN1640A,LOGGER,ECU,JETSON
 SG_ LinkQuality : 48|8@1+ (1,0) [0|255] "%"  VN1640A,LOGGER,JETSON
 SG_ K3_Button : 2|1@1+ (1,0) [0|0] ""  VN1640A,LOGGER,JETSON
 SG_ K2_Switch : 1|1@1+ (1,0) [0|0] ""  VN1640A,LOGGER,JETSON
 SG_ K1_eStop : 0|1@1+ (1,0) [0|0] ""  VN1640A,LOGGER,JETSON

BO_ 1164 CANO_EPOS_TPDO4: 6 EPOS
 SG_ statusword : 0|16@1+ (1,0) [0|65535] ""  VN1640A,LOGGER,JETSON
 SG_ velocity_actual_value : 16|32@1- (1,0) [-2147483648|2147483647] ""  VN1640A,LOGGER,JETSON

BO_ 908 CANO_EPOS_TPDO3: 6 EPOS
 SG_ statusword : 0|16@1+ (1,0) [0|65535] ""  VN1640A,LOGGER,JETSON
 SG_ position_actual_value : 16|32@1- (1,0) [-2147483648|2147483647] ""  VN1640A,LOGGER,JETSON

BO_ 652 CANO_EPOS_TPDO2: 3 EPOS
 SG_ statusword : 0|16@1+ (1,0) [0|65535] ""  LOGGER,VN1640A,JETSON
 SG_ modes_of_operation_disp : 16|8@1+ (1,0) [0|255] ""  LOGGER,VN1640A,JETSON

BO_ 396 CANO_EPOS_TPDO1: 2 EPOS
 SG_ statusword : 0|16@1+ (1,0) [0|65535] ""  VN1640A,LOGGER,JETSON

BO_ 256 CANO_TIME: 6 JETSON

BO_ 140 CANO_EPOS_EMCY: 8 EPOS

BO_ 128 CANO_SYNC: 0 JETSON

BO_ 0 CANO_NMT_Node_Control: 2 JETSON
 SG_ Addressed_Node_ID : 8|8@1+ (1,0) [0|255] ""  VN1640A,LOGGER,RES,EPOS
 SG_ Requested_State : 0|8@1+ (1,0) [0|255] ""  VN1640A,LOGGER,RES,EPOS

BO_ 1168 CAL_SteeringAngle: 2 AIN_F2
 SG_ Voltage : 0|12@1+ (1,0) [0|4095] "mV"  LOGGER,VN1640A

BO_ 1167 CAL_APPS: 6 AIN_F1
 SG_ Upper_5V : 24|12@1+ (1.22,0) [0|4995.9] "mV"  LOGGER,VN1640A
 SG_ Lower_5V : 36|12@1+ (1.22,0) [0|4995.9] "mV"  LOGGER,VN1640A
 SG_ Lower_3V3 : 12|12@1+ (1,0) [0|4095] "mV"  LOGGER,VN1640A
 SG_ Upper_3V3 : 0|12@1+ (1,0) [0|4095] "mV"  LOGGER,VN1640A

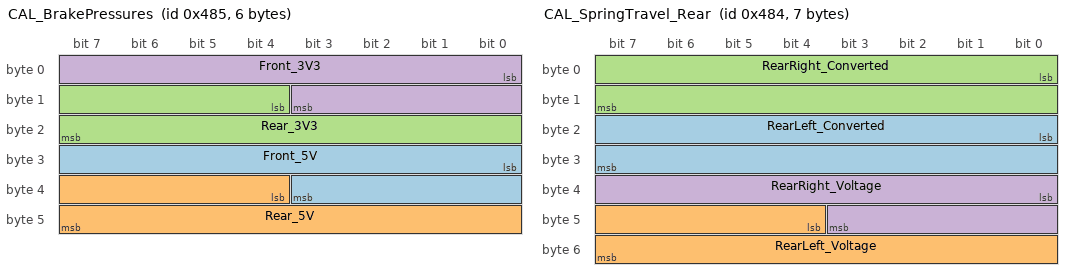
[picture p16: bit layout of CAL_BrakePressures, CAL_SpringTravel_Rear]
BO_ 1157 CAL_BrakePressures: 6 AIN_F1
 SG_ Front_5V : 24|12@1+ (1.22,0) [0|4995.9] "mV"  LOGGER,VN1640A
 SG_ Rear_5V : 36|12@1+ (1.22,0) [0|4995.9] "mV"  LOGGER,VN1640A
 SG_ Rear_3V3 : 12|12@1+ (1,0) [0|4095] "mV"  LOGGER,VN1640A
 SG_ Front_3V3 : 0|12@1+ (1,0) [0|4095] "mV"  LOGGER,VN1640A

BO_ 1156 CAL_SpringTravel_Rear: 7 AIN_R1
 SG_ RearLeft_Converted : 16|16@1- (0.01,195) [-132.68|522.67] "mm"  LOGGER,VN1640A
 SG_ RearLeft_Voltage : 44|12@1+ (1,0) [0|4095] "mV"  LOGGER,VN1640A
 SG_ RearRight_Converted : 0|16@1- (0.01,195) [-132.68|522.67] "mm"  LOGGER,VN1640A
 SG_ RearRight_Voltage : 32|12@1+ (1,0) [0|4095] "mV"  LOGGER,VN1640A

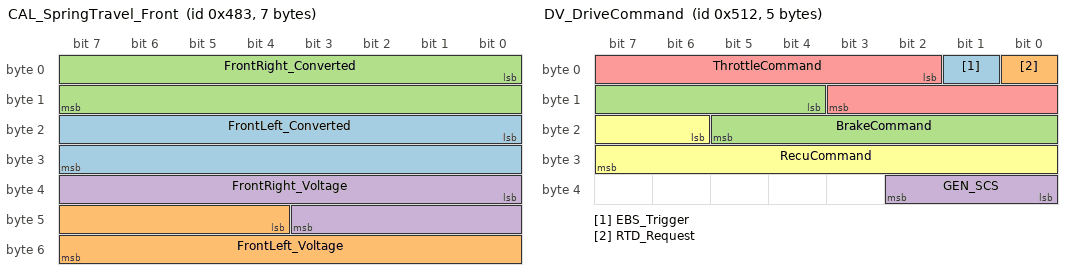
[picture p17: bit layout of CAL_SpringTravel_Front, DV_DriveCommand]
BO_ 1155 CAL_SpringTravel_Front: 7 AIN_F2
 SG_ FrontLeft_Converted : 16|16@1- (0.01,195) [-132.68|522.67] "mm"  LOGGER,VN1640A
 SG_ FrontLeft_Voltage : 44|12@1+ (1,0) [0|4095] "mV"  LOGGER,VN1640A
 SG_ FrontRight_Converted : 0|16@1- (0.01,195) [-132.68|522.67] "mm"  LOGGER,VN1640A
 SG_ FrontRight_Voltage : 32|12@1+ (1,0) [0|4095] "mV"  LOGGER,VN1640A

BO_ 1152 CAL_CalibrationMaster: 1 VN1640A

BO_ 1298 DV_DriveCommand: 5 JETSON
 SG_ EBS_Trigger : 1|1@1+ (1,0) [0|1] ""  VN1640A,LOGGER,FSG_LOGGER,ASB
 SG_ RTD_Request : 0|1@1+ (1,0) [0|1] ""  VN1640A,LOGGER,FSG_LOGGER,ECU
 SG_ BrakeCommand : 12|10@1+ (0.1,0) [0|102.3] "%"  VN1640A,LOGGER,FSG_LOGGER,ASB
 SG_ GEN_SCS : 32|3@1+ (1,0) [0|7] ""  VN1640A,LOGGER,HSS_REAR,ECU,FSG_LOGGER,ASB
 SG_ ThrottleCommand : 2|10@1+ (0.1,0) [0|102.3] "%"  VN1640A,LOGGER,ECU,FSG_LOGGER
 SG_ RecuCommand : 22|10@1+ (0.1,0) [0|102.3] "%"  VN1640A,LOGGER,HSS_REAR,ECU,FSG_LOGGER

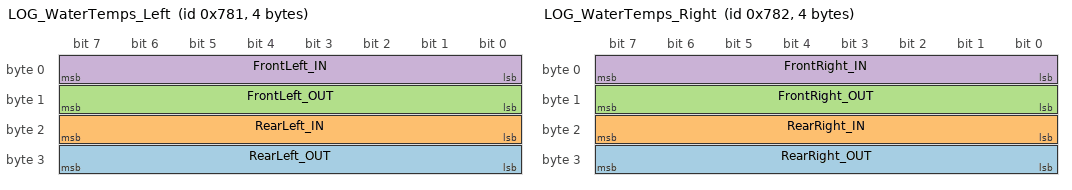
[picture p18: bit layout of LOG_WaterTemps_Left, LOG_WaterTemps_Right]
BO_ 1921 LOG_WaterTemps_Left: 4 AIN_SB_L
 SG_ RearLeft_OUT : 24|8@1+ (0.5,0) [0|127.5] "°C"  VN1640A,LOGGER
 SG_ RearLeft_IN : 16|8@1+ (0.5,0) [0|127.5] "°C"  VN1640A,LOGGER
 SG_ FrontLeft_OUT : 8|8@1+ (0.5,0) [0|127.5] "°C"  VN1640A,LOGGER
 SG_ FrontLeft_IN : 0|8@1+ (0.5,0) [0|127.5] "°C"  VN1640A,LOGGER

BO_ 1922 LOG_WaterTemps_Right: 4 AIN_SB_R
 SG_ RearRight_OUT : 24|8@1+ (0.5,0) [0|127.5] "°C"  VN1640A,LOGGER
 SG_ RearRight_IN : 16|8@1+ (0.5,0) [0|127.5] "°C"  VN1640A,LOGGER
 SG_ FrontRight_OUT : 8|8@1+ (0.5,0) [0|127.5] "°C"  VN1640A,LOGGER
 SG_ FrontRight_IN : 0|8@1+ (0.5,0) [0|127.5] "°C"  VN1640A,LOGGER

BO_ 1923 LOG_SpringTravel_Front: 4 AIN_F2
 SG_ FrontRight : 16|16@1- (0.01,0) [-132.68|522.67] "mm"  VN1640A,LOGGER
 SG_ FrontLeft : 0|16@1- (0.01,0) [-132.68|522.67] "mm"  VN1640A,LOGGER

BO_ 1924 LOG_SpringTravel_Rear: 4 AIN_R1
 SG_ RearRight : 16|16@1- (0.01,0) [-327.68|327.67] "mm"  VN1640A,LOGGER
 SG_ RearLeft : 0|16@1- (0.01,0) [-327.68|327.67] "mm"  VN1640A,LOGGER

BO_ 1301 LOG_BrakePressures: 3 AIN_F1
 SG_ Rear : 12|12@1+ (50,0) [0|204750] "mBar"  JETSON,VN1640A,ASB,LOGGER
 SG_ Front : 0|12@1+ (50,0) [0|204750] "mBar"  JETSON,VN1640A,ASB,LOGGER

BO_ 1926 LOG_LEM: 2 AIN_R1
 SG_ LV : 0|16@1+ (1,0) [0|65535] "mA"  VN1640A,LOGGER

BO_ 1927 LOG_DashLEDs: 1 DIO_DASH
 SG_ AMS : 2|1@1+ (1,0) [0|1] ""  VN1640A,LOGGER
 SG_ IMD : 0|1@1+ (1,0) [0|1] ""  VN1640A,LOGGER

BO_ 1928 LOG_BME280s_Left: 0 I2C_SB_L

BO_ 1929 LOG_BME280s_Right: 0 I2C_SB_R

BO_ 1930 LOG_BME280s_Front: 0 I2C_FW

BO_ 1931 LOG_BME280s_Rear: 0 I2C_RW

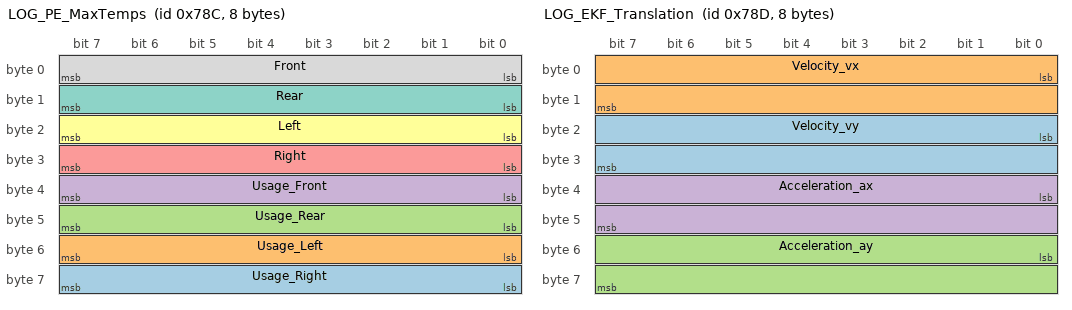
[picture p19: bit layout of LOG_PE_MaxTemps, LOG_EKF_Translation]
BO_ 1932 LOG_PE_MaxTemps: 8 ECU
 SG_ Usage_Right : 56|8@1+ (0.5,0) [0|127.5] "%"  VN1640A,LOGGER
 SG_ Usage_Left : 48|8@1+ (0.5,0) [0|127.5] "%"  LOGGER,VN1640A
 SG_ Usage_Rear : 40|8@1+ (0.5,0) [0|127.5] "%"  VN1640A,LOGGER
 SG_ Usage_Front : 32|8@1+ (0.5,0) [0|127.5] "%"  VN1640A,LOGGER
 SG_ Right : 24|8@1+ (0.6,0) [0|153] "°C"  VN1640A,LOGGER
 SG_ Left : 16|8@1+ (0.6,0) [0|153] "°C"  LOGGER,VN1640A
 SG_ Rear : 8|8@1+ (0.6,0) [0|153] "°C"  VN1640A,LOGGER
 SG_ Front : 0|8@1+ (0.6,0) [0|153] "°C"  VN1640A,LOGGER

BO_ 1933 LOG_EKF_Translation: 8 ECU
 SG_ Velocity_vy : 16|16@1- (0.002,0) [-65.536|65.534] "m/s"  VN1640A,LOGGER
 SG_ Velocity_vx : 0|16@1- (0.002,0) [-65.536|65.534] "m/s"  VN1640A,LOGGER
 SG_ Acceleration_ay : 48|16@1- (0.002,0) [-65.536|65.534] "m/s^2"  VN1640A,LOGGER
 SG_ Acceleration_ax : 32|16@1- (0.002,0) [-65.536|65.534] "m/s^2"  VN1640A,LOGGER

BO_ 1934 LOG_EKF_Rotation: 8 ECU
 SG_ YawRate : 16|16@1- (0.00018,0) [-5.89824|5.89806] "rad/s"  VN1640A,LOGGER
 SG_ Heading_psi : 0|16@1- (0.0003,0) [-9.8304|9.8301] "rad"  VN1640A,LOGGER

BO_ 2020 CANO_TLSS: 8 JETSON

BO_ 2021 CANO_RLSS: 8 JETSON

CM_ BU_ AMI "Autonomous Mission Indicator";
CM_ BU_ ECU "Engine Control unit. It is the Main Unit inside of the Vehicle. The Hardware is either the Micro AutoBox II (uab) or the own develaped JoBaBox (Jonas Bauernfeind Box).
";
CM_ BO_ 3221225472 "This is a message for not used signals, created by Vector CANdb++ DBC OLE DB Provider.";
CM_ SG_ 296 odo_time_sync "Set to 1 if the velocity information is correctly time synchronized.";
CM_ SG_ 296 odo_real_meas "Set to 1 if this log comes from a real pulse measurement or 0 if it comes from a timeout.";
CM_ BO_ 902 "CAN NOT BE USED FOR SCS TASKS";
CM_ SG_ 902 TempAvg "Average Tempratur of the Cells";
CM_ SG_ 902 TempMax "Maximum Tempratur of the Cells";
CM_ SG_ 902 TempMin "Minimum Tempratur of the Cells";
CM_ BO_ 901 "CAN NOT BE USED FOR SCS TASKS";
CM_ SG_ 901 Power "Current Power Draw";
CM_ SG_ 901 SOC_Internal "State of Charge";
CM_ SG_ 901 State "State of the Battery/BatPCB";
CM_ BO_ 900 "CAN NOT BE USED FOR SCS TASKS";
CM_ BO_ 899 "CAN NOT BE USED FOR SCS TASKS";
CM_ BO_ 898 "CAN NOT BE USED FOR SCS TASKS";
CM_ BO_ 897 "CAN NOT BE USED FOR SCS TASKS";
CM_ SG_ 259 GEN_SCS "3 Bit Application side Incrementing Value to show active Message creation and detection of missing messages, when on reciver side the recived time stamp not avalible is.";
CM_ SG_ 386 GEN_SCS "3 Bit Application side Incrementing Value to show active Message creation and detection of missing messages, when on reciver side the recived time stamp not avalible is.";
CM_ SG_ 385 GEN_SCS "3 Bit Application side Incrementing Value to show active Message creation and detection of missing messages, when on reciver side the recived time stamp not avalible is.";
CM_ SG_ 89 GEN_SCS "3 Bit Application side Incrementing Value to show active Message creation and detection of missing messages, when on reciver side the recived time stamp not avalible is.";
CM_ SG_ 88 GEN_SCS "3 Bit Application side Incrementing Value to show active Message creation and detection of missing messages, when on reciver side the recived time stamp not avalible is.";
CM_ SG_ 87 GEN_SCS "3 Bit Application side Incrementing Value to show active Message creation and detection of missing messages, when on reciver side the recived time stamp not avalible is.";
CM_ SG_ 86 GEN_SCS "3 Bit Application side Incrementing Value to show active Message creation and detection of missing messages, when on reciver side the recived time stamp not avalible is.";
CM_ SG_ 85 GEN_SCS "3 Bit Application side Incrementing Value to show active Message creation and detection of missing messages, when on reciver side the recived time stamp not avalible is.";
CM_ SG_ 84 GEN_SCS "3 Bit Application side Incrementing Value to show active Message creation and detection of missing messages, when on reciver side the recived time stamp not avalible is.";
CM_ SG_ 82 GEN_SCS "3 Bit Application side Incrementing Value to show active Message creation and detection of missing messages, when on reciver side the recived time stamp not avalible is.";
CM_ SG_ 81 GEN_SCS "3 Bit Application side Incrementing Value to show active Message creation and detection of missing messages, when on reciver side the recived time stamp not avalible is.";
CM_ SG_ 80 GEN_SCS "3 Bit Application side Incrementing Value to show active Message creation and detection of missing messages, when on reciver side the recived time stamp not avalible is.";
CM_ SG_ 261 GEN_SCS "3 Bit Application side Incrementing Value to show active Message creation and detection of missing messages, when on reciver side the recived time stamp not avalible is.";
CM_ SG_ 261 Steering_Angle "Angle from the Vehicle center line in the direction of travel (Calculated).";
CM_ SG_ 261 SteeringWheel_Angle "Angle of the Steering Wheel";
CM_ SG_ 260 GEN_SCS "3 Bit Application side Incrementing Value to show active Message creation and detection of missing messages, when on reciver side the recived time stamp not avalible is.";
CM_ SG_ 260 Brake_Pressed "If the Brake Pressure are exceeding a certain value the Brakes are flaged as Pressed.";
CM_ SG_ 260 Throttle "Throttle Value calculated from the APPS and send as Procent.";
CM_ SG_ 1285 GEN_SCS "3 Bit Application side Incrementing Value to show active Message creation and detection of missing messages, when on reciver side the recived time stamp not avalible is.";
CM_ SG_ 1283 GEN_SCS "3 Bit Application side Incrementing Value to show active Message creation and detection of missing messages, when on reciver side the recived time stamp not avalible is.";
CM_ SG_ 1168 Voltage "0 Volt to 3.3 Volt from the ADC input pin";
CM_ SG_ 1167 Upper_5V "0 Volt to 5 Volt from the ADC input pin";
CM_ SG_ 1167 Lower_5V "0 Volt to 5 Volt from the ADC input pin";
CM_ SG_ 1167 Lower_3V3 "0 Volt to 3.3 Volt from the ADC input pin";
CM_ SG_ 1167 Upper_3V3 "0 Volt to 3.3 Volt from the ADC input pin";
CM_ SG_ 1157 Front_5V "0 Volt to 3.3 Volt from the ADC input pin";
CM_ SG_ 1157 Rear_5V "0 Volt to 3.3 Volt from the ADC input pin";
CM_ SG_ 1157 Rear_3V3 "0 Volt to 3.3 Volt from the ADC input pin";
CM_ SG_ 1157 Front_3V3 "0 Volt to 3.3 Volt from the ADC input pin";
CM_ SG_ 1156 RearLeft_Voltage "0 Volt to 3.3 Volt from the ADC input pin";
CM_ SG_ 1156 RearRight_Voltage "0 Volt to 3.3 Volt from the ADC input pin";
CM_ SG_ 1155 FrontLeft_Voltage "0 Volt to 3.3 Volt from the ADC input pin";
CM_ SG_ 1155 FrontRight_Voltage "0 Volt to 3.3 Volt from the ADC input pin";
CM_ SG_ 1298 GEN_SCS "3 Bit Application side Incrementing Value to show active Message creation and detection of missing messages, when on reciver side the recived time stamp not avalible is.";
CM_ SG_ 1926 LV "Low Voltage LEM Sensor

50 Amper Variante
LV Sagt 1 - 0.2 Hz reicht aus.
Accuracy +-1.25%;
Respnse time 3.5 us
Output Voltage 0-5V 
";
CM_ BO_ 1932 "Max Temps for each Power Electronic Group. Groups are split PE Housings, so PE Front Right and Front Left are one Groupe and showes the highest Temp from either IGBT, Inverter, or Motor.";
CM_ SG_ 1932 Usage_Right "Gives the Temprature headroom in procent of the PE components on the Right.";
CM_ SG_ 1932 Usage_Left "Gives the Temprature headroom in procent of the PE components on the Left.";
CM_ SG_ 1932 Usage_Rear "Gives the Temprature headroom in procent of the PE components in the Rear.";
CM_ SG_ 1932 Usage_Front "Gives the Temprature headroom in procent of the PE components in the Front.";
BA_DEF_  "BusType" STRING ;
BA_DEF_  "BaudRate" INT 10000 1000000;
BA_DEF_ BO_  "GenMsgSendType" ENUM  "cyclic","spontaneous","cyclicIfActive","spontaneousWithDelay","cyclicAndSpontaneous","cyclicAndSpontaneousWithDelay","spontaneousWithRepetition","cyclicIfActiveAndSpontaneousWD";
BA_DEF_ BO_  "GenMsgCycleTime" INT 1 1000;
BA_DEF_  "GenAuthor" STRING ;
BA_DEF_DEF_  "BusType" "";
BA_DEF_DEF_  "BaudRate" 500000;
BA_DEF_DEF_  "GenMsgSendType" "cyclic";
BA_DEF_DEF_  "GenMsgCycleTime" 100;
BA_DEF_DEF_  "GenAuthor" "";
BA_ "GenAuthor" "Richard Frei";
BA_ "BaudRate" 1000000;
BA_ "BusType" "CAN";
BA_ "GenMsgSendType" BO_ 1936 1;
BA_ "GenMsgCycleTime" BO_ 263 10;
BA_ "GenMsgCycleTime" BO_ 262 10;
BA_ "GenMsgCycleTime" BO_ 259 10;
BA_ "GenMsgSendType" BO_ 259 4;
BA_ "GenMsgSendType" BO_ 386 4;
BA_ "GenMsgSendType" BO_ 385 4;
BA_ "GenMsgSendType" BO_ 89 4;
BA_ "GenMsgSendType" BO_ 88 4;
BA_ "GenMsgSendType" BO_ 87 4;
BA_ "GenMsgSendType" BO_ 86 4;
BA_ "GenMsgSendType" BO_ 85 4;
BA_ "GenMsgSendType" BO_ 84 4;
BA_ "GenMsgSendType" BO_ 82 4;
BA_ "GenMsgSendType" BO_ 81 4;
BA_ "GenMsgSendType" BO_ 80 4;
BA_ "GenMsgCycleTime" BO_ 261 10;
BA_ "GenMsgCycleTime" BO_ 260 10;
BA_ "GenMsgSendType" BO_ 1809 1;
BA_ "GenMsgSendType" BO_ 1804 1;
BA_ "GenMsgSendType" BO_ 1553 1;
BA_ "GenMsgSendType" BO_ 1548 1;
BA_ "GenMsgSendType" BO_ 1425 1;
BA_ "GenMsgSendType" BO_ 1420 1;
BA_ "GenMsgSendType" BO_ 1300 2;
BA_ "GenMsgSendType" BO_ 145 1;
BA_ "GenMsgCycleTime" BO_ 1297 10;
BA_ "GenMsgCycleTime" BO_ 1283 10;
BA_ "GenMsgSendType" BO_ 1169 1;
BA_ "GenMsgSendType" BO_ 913 1;
BA_ "GenMsgSendType" BO_ 657 1;
BA_ "GenMsgSendType" BO_ 1041 1;
BA_ "GenMsgSendType" BO_ 785 1;
BA_ "GenMsgSendType" BO_ 529 1;
BA_ "GenMsgCycleTime" BO_ 401 30;
BA_ "GenMsgSendType" BO_ 256 1;
BA_ "GenMsgSendType" BO_ 140 1;
BA_ "GenMsgSendType" BO_ 128 1;
BA_ "GenMsgSendType" BO_ 0 1;
BA_ "GenMsgSendType" BO_ 1168 2;
BA_ "GenMsgSendType" BO_ 1167 2;
BA_ "GenMsgSendType" BO_ 1157 2;
BA_ "GenMsgSendType" BO_ 1156 2;
BA_ "GenMsgSendType" BO_ 1155 2;
BA_ "GenMsgSendType" BO_ 1152 2;
BA_ "GenMsgCycleTime" BO_ 1298 10;
BA_ "GenMsgCycleTime" BO_ 1921 500;
BA_ "GenMsgCycleTime" BO_ 1922 500;
BA_ "GenMsgCycleTime" BO_ 1301 10;
BA_ "GenMsgSendType" BO_ 1927 1;
BA_ "GenMsgSendType" BO_ 2020 1;
BA_ "GenMsgSendType" BO_ 2021 1;
VAL_ 259 State 6 "SCS ERROR" 5 "LC ON" 4 "DRIVE" 3 "Wait for RTD" 2 "RTD OFF" 1 "Wait for TSA" 0 "Undefined | Startup" ;
VAL_ 0 Addressed_Node_ID 17 "RES" 12 "EPOS" 0 "all" ;
VAL_ 0 Requested_State 130 "Reset Communication" 129 "Reset Application" 2 "Stopped Mode" 128 "Pre-Operational Mode" 1 "Operational Mode" ;
